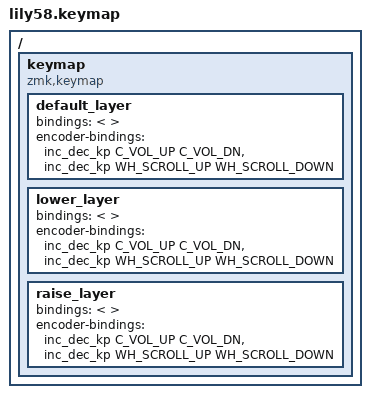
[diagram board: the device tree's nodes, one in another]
/ {
    keymap {
        compatible = "zmk,keymap";

        default_layer {
            bindings = <
                /* TU LAYOUT NORMAL AQUÍ */
            >;

            /* ENCÓDERES LEGACY */
            encoder-bindings = <
                /* Encoder izquierdo */
                &inc_dec_kp C_VOL_UP C_VOL_DN

                /* Encoder derecho */
                &inc_dec_kp WH_SCROLL_UP WH_SCROLL_DOWN
            >;
        };

        lower_layer {
            bindings = < /* igual que antes */ >;

            encoder-bindings = <
                &inc_dec_kp C_VOL_UP C_VOL_DN
                &inc_dec_kp WH_SCROLL_UP WH_SCROLL_DOWN
            >;
        };

        raise_layer {
            bindings = < /* igual que antes */ >;

            encoder-bindings = <
                &inc_dec_kp C_VOL_UP C_VOL_DN
                &inc_dec_kp WH_SCROLL_UP WH_SCROLL_DOWN
            >;
        };
    };
};
